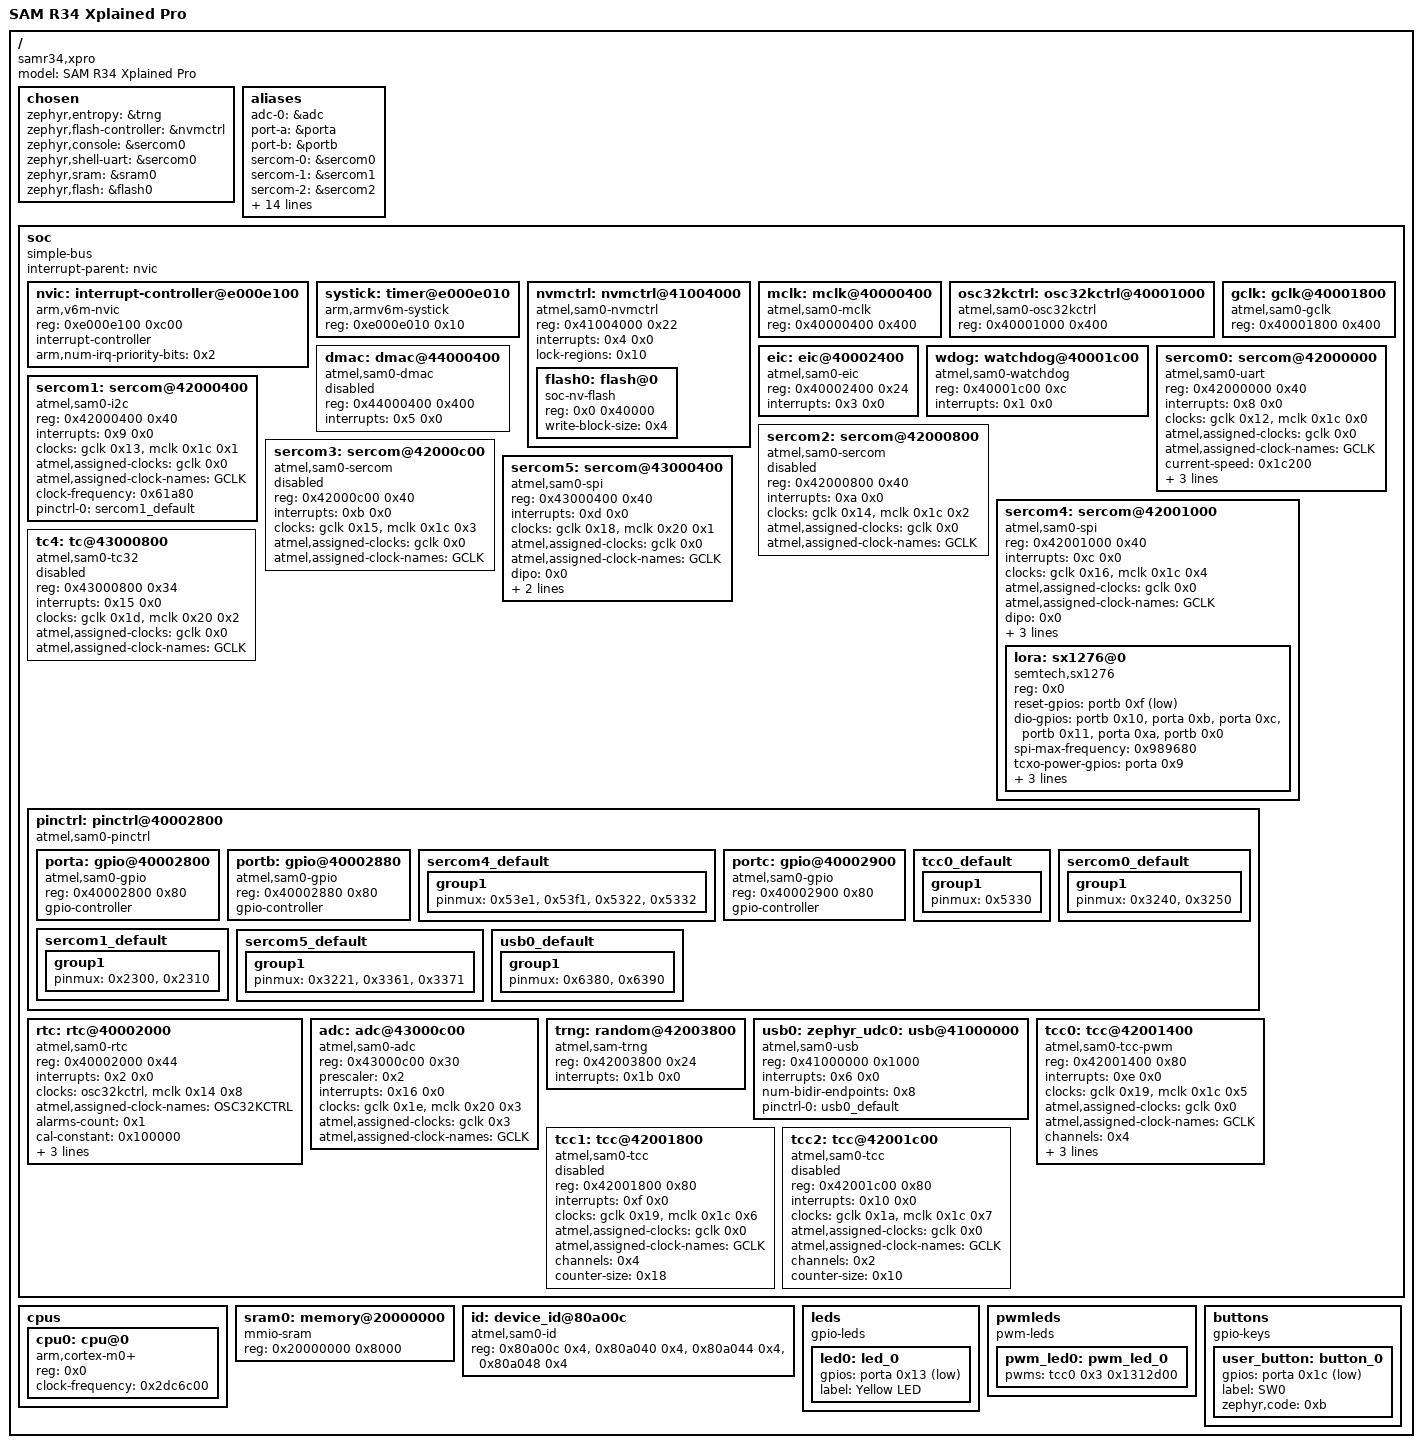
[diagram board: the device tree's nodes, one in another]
/dts-v1/;

/* node '/' defined in zephyr/dts/common/skeleton.dtsi:9 */
/ {
	#address-cells = < 0x1 >;        /* in zephyr/dts/common/skeleton.dtsi:10 */
	#size-cells = < 0x1 >;           /* in zephyr/dts/common/skeleton.dtsi:11 */
	model = "SAM R34 Xplained Pro";  /* in zephyr/boards/atmel/sam0/samr34_xpro/samr34_xpro.dts:14 */
	compatible = "samr34,xpro",
	             "atmel,samr34j18b",
	             "atmel,samr34";     /* in zephyr/boards/atmel/sam0/samr34_xpro/samr34_xpro.dts:15 */

	/* node '/chosen' defined in zephyr/dts/common/skeleton.dtsi:13 */
	chosen {
		zephyr,entropy = &trng;             /* in zephyr/dts/arm/atmel/saml2x.dtsi:37 */
		zephyr,flash-controller = &nvmctrl; /* in zephyr/dts/arm/atmel/saml2x.dtsi:38 */
		zephyr,console = &sercom0;          /* in zephyr/boards/atmel/sam0/samr34_xpro/samr34_xpro.dts:18 */
		zephyr,shell-uart = &sercom0;       /* in zephyr/boards/atmel/sam0/samr34_xpro/samr34_xpro.dts:19 */
		zephyr,sram = &sram0;               /* in zephyr/boards/atmel/sam0/samr34_xpro/samr34_xpro.dts:20 */
		zephyr,flash = &flash0;             /* in zephyr/boards/atmel/sam0/samr34_xpro/samr34_xpro.dts:21 */
	};

	/* node '/aliases' defined in zephyr/dts/common/skeleton.dtsi:15 */
	aliases {
		adc-0 = &adc;         /* in zephyr/dts/arm/atmel/saml2x.dtsi:17 */
		port-a = &porta;      /* in zephyr/dts/arm/atmel/saml2x.dtsi:19 */
		port-b = &portb;      /* in zephyr/dts/arm/atmel/saml2x.dtsi:20 */
		sercom-0 = &sercom0;  /* in zephyr/dts/arm/atmel/saml2x.dtsi:22 */
		sercom-1 = &sercom1;  /* in zephyr/dts/arm/atmel/saml2x.dtsi:23 */
		sercom-2 = &sercom2;  /* in zephyr/dts/arm/atmel/saml2x.dtsi:24 */
		sercom-3 = &sercom3;  /* in zephyr/dts/arm/atmel/saml2x.dtsi:25 */
		sercom-4 = &sercom4;  /* in zephyr/dts/arm/atmel/saml2x.dtsi:26 */
		sercom-5 = &sercom5;  /* in zephyr/dts/arm/atmel/saml2x.dtsi:27 */
		rtc = &rtc;           /* in zephyr/dts/arm/atmel/saml2x.dtsi:29 */
		tc-4 = &tc4;          /* in zephyr/dts/arm/atmel/saml2x.dtsi:31 */
		watchdog0 = &wdog;    /* in zephyr/dts/arm/atmel/saml2x.dtsi:33 */
		tcc-0 = &tcc0;        /* in zephyr/dts/arm/atmel/saml21.dtsi:12 */
		tcc-1 = &tcc1;        /* in zephyr/dts/arm/atmel/saml21.dtsi:13 */
		tcc-2 = &tcc2;        /* in zephyr/dts/arm/atmel/saml21.dtsi:14 */
		port-c = &portc;      /* in zephyr/dts/arm/atmel/samr34.dtsi:16 */
		lora0 = &lora;        /* in zephyr/dts/arm/atmel/samr34.dtsi:18 */
		led0 = &led0;         /* in zephyr/boards/atmel/sam0/samr34_xpro/samr34_xpro.dts:26 */
		pwm-led0 = &pwm_led0; /* in zephyr/boards/atmel/sam0/samr34_xpro/samr34_xpro.dts:27 */
		sw0 = &user_button;   /* in zephyr/boards/atmel/sam0/samr34_xpro/samr34_xpro.dts:28 */
	};

	/* node '/soc' defined in zephyr/dts/arm/armv6-m.dtsi:6 */
	soc {
		#address-cells = < 0x1 >;     /* in zephyr/dts/arm/armv6-m.dtsi:7 */
		#size-cells = < 0x1 >;        /* in zephyr/dts/arm/armv6-m.dtsi:8 */
		compatible = "simple-bus";    /* in zephyr/dts/arm/armv6-m.dtsi:9 */
		interrupt-parent = < &nvic >; /* in zephyr/dts/arm/armv6-m.dtsi:10 */
		ranges;                       /* in zephyr/dts/arm/armv6-m.dtsi:11 */

		/* node '/soc/interrupt-controller@e000e100' defined in zephyr/dts/arm/armv6-m.dtsi:13 */
		nvic: interrupt-controller@e000e100 {
			#address-cells = < 0x1 >;            /* in zephyr/dts/arm/armv6-m.dtsi:14 */
			compatible = "arm,v6m-nvic";         /* in zephyr/dts/arm/armv6-m.dtsi:15 */
			reg = < 0xe000e100 0xc00 >;          /* in zephyr/dts/arm/armv6-m.dtsi:16 */
			interrupt-controller;                /* in zephyr/dts/arm/armv6-m.dtsi:17 */
			#interrupt-cells = < 0x2 >;          /* in zephyr/dts/arm/armv6-m.dtsi:18 */
			arm,num-irq-priority-bits = < 0x2 >; /* in zephyr/dts/arm/atmel/saml2x.dtsi:249 */
			phandle = < 0x1 >;                   /* in zephyr/dts/arm/armv6-m.dtsi:10 */
		};

		/* node '/soc/timer@e000e010' defined in zephyr/dts/arm/armv6-m.dtsi:21 */
		systick: timer@e000e010 {
			compatible = "arm,armv6m-systick"; /* in zephyr/dts/arm/armv6-m.dtsi:22 */
			reg = < 0xe000e010 0x10 >;         /* in zephyr/dts/arm/armv6-m.dtsi:23 */
		};

		/* node '/soc/nvmctrl@41004000' defined in zephyr/dts/arm/atmel/saml2x.dtsi:67 */
		nvmctrl: nvmctrl@41004000 {
			compatible = "atmel,sam0-nvmctrl"; /* in zephyr/dts/arm/atmel/saml2x.dtsi:68 */
			reg = < 0x41004000 0x22 >;         /* in zephyr/dts/arm/atmel/saml2x.dtsi:69 */
			interrupts = < 0x4 0x0 >;          /* in zephyr/dts/arm/atmel/saml2x.dtsi:70 */
			#address-cells = < 0x1 >;          /* in zephyr/dts/arm/atmel/saml2x.dtsi:72 */
			#size-cells = < 0x1 >;             /* in zephyr/dts/arm/atmel/saml2x.dtsi:73 */
			lock-regions = < 0x10 >;           /* in zephyr/dts/arm/atmel/saml2x.dtsi:75 */

			/* node '/soc/nvmctrl@41004000/flash@0' defined in zephyr/dts/arm/atmel/saml2x.dtsi:77 */
			flash0: flash@0 {
				compatible = "soc-nv-flash"; /* in zephyr/dts/arm/atmel/saml2x.dtsi:78 */
				reg = < 0x0 0x40000 >;       /* in zephyr/dts/arm/atmel/saml2x.dtsi:79 */
				write-block-size = < 0x4 >;  /* in zephyr/dts/arm/atmel/saml2x.dtsi:81 */
			};
		};

		/* node '/soc/mclk@40000400' defined in zephyr/dts/arm/atmel/saml2x.dtsi:85 */
		mclk: mclk@40000400 {
			compatible = "atmel,sam0-mclk"; /* in zephyr/dts/arm/atmel/saml2x.dtsi:86 */
			reg = < 0x40000400 0x400 >;     /* in zephyr/dts/arm/atmel/saml2x.dtsi:87 */
			#clock-cells = < 0x2 >;         /* in zephyr/dts/arm/atmel/saml2x.dtsi:89 */
			phandle = < 0x3 >;              /* in zephyr/dts/arm/atmel/saml21.dtsi:72 */
		};

		/* node '/soc/osc32kctrl@40001000' defined in zephyr/dts/arm/atmel/saml2x.dtsi:92 */
		osc32kctrl: osc32kctrl@40001000 {
			compatible = "atmel,sam0-osc32kctrl";  /* in zephyr/dts/arm/atmel/saml2x.dtsi:93 */
			reg = < 0x40001000 0x400 >;            /* in zephyr/dts/arm/atmel/saml2x.dtsi:94 */
			#clock-cells = < 0x0 >;                /* in zephyr/dts/arm/atmel/saml2x.dtsi:96 */
			#atmel,assigned-clock-cells = < 0x1 >; /* in zephyr/dts/arm/atmel/saml2x.dtsi:97 */
			phandle = < 0xa >;                     /* in zephyr/dts/arm/atmel/saml2x.dtsi:203 */
		};

		/* node '/soc/gclk@40001800' defined in zephyr/dts/arm/atmel/saml2x.dtsi:100 */
		gclk: gclk@40001800 {
			compatible = "atmel,sam0-gclk";        /* in zephyr/dts/arm/atmel/saml2x.dtsi:101 */
			reg = < 0x40001800 0x400 >;            /* in zephyr/dts/arm/atmel/saml2x.dtsi:102 */
			#clock-cells = < 0x1 >;                /* in zephyr/dts/arm/atmel/saml2x.dtsi:104 */
			#atmel,assigned-clock-cells = < 0x1 >; /* in zephyr/dts/arm/atmel/saml2x.dtsi:105 */
			phandle = < 0x2 >;                     /* in zephyr/dts/arm/atmel/saml21.dtsi:72 */
		};

		/* node '/soc/dmac@44000400' defined in zephyr/dts/arm/atmel/saml2x.dtsi:108 */
		dmac: dmac@44000400 {
			compatible = "atmel,sam0-dmac"; /* in zephyr/dts/arm/atmel/saml2x.dtsi:109 */
			reg = < 0x44000400 0x400 >;     /* in zephyr/dts/arm/atmel/saml2x.dtsi:110 */
			interrupts = < 0x5 0x0 >;       /* in zephyr/dts/arm/atmel/saml2x.dtsi:111 */
			status = "disabled";            /* in zephyr/dts/arm/atmel/saml2x.dtsi:112 */
			#dma-cells = < 0x2 >;           /* in zephyr/dts/arm/atmel/saml2x.dtsi:114 */
		};

		/* node '/soc/eic@40002400' defined in zephyr/dts/arm/atmel/saml2x.dtsi:117 */
		eic: eic@40002400 {
			compatible = "atmel,sam0-eic"; /* in zephyr/dts/arm/atmel/saml2x.dtsi:118 */
			reg = < 0x40002400 0x24 >;     /* in zephyr/dts/arm/atmel/saml2x.dtsi:119 */
			interrupts = < 0x3 0x0 >;      /* in zephyr/dts/arm/atmel/saml2x.dtsi:120 */
		};

		/* node '/soc/watchdog@40001c00' defined in zephyr/dts/arm/atmel/saml2x.dtsi:123 */
		wdog: watchdog@40001c00 {
			compatible = "atmel,sam0-watchdog"; /* in zephyr/dts/arm/atmel/saml2x.dtsi:124 */
			reg = < 0x40001c00 0xc >;           /* in zephyr/dts/arm/atmel/saml2x.dtsi:125 */
			interrupts = < 0x1 0x0 >;           /* in zephyr/dts/arm/atmel/saml2x.dtsi:126 */
		};

		/* node '/soc/sercom@42000000' defined in zephyr/dts/arm/atmel/saml2x.dtsi:129 */
		sercom0: sercom@42000000 {
			reg = < 0x42000000 0x40 >;             /* in zephyr/dts/arm/atmel/saml2x.dtsi:131 */
			interrupts = < 0x8 0x0 >;              /* in zephyr/dts/arm/atmel/saml21.dtsi:71 */
			clocks = < &gclk 0x12 >,
			         < &mclk 0x1c 0x0 >;           /* in zephyr/dts/arm/atmel/saml21.dtsi:72 */
			clock-names = "GCLK",
			              "MCLK";                  /* in zephyr/dts/arm/atmel/saml21.dtsi:73 */
			atmel,assigned-clocks = < &gclk 0x0 >; /* in zephyr/dts/arm/atmel/saml21.dtsi:74 */
			atmel,assigned-clock-names = "GCLK";   /* in zephyr/dts/arm/atmel/saml21.dtsi:75 */
			status = "okay";                       /* in zephyr/boards/atmel/sam0/samr34_xpro/samr34_xpro.dts:87 */
			compatible = "atmel,sam0-uart";        /* in zephyr/boards/atmel/sam0/samr34_xpro/samr34_xpro.dts:88 */
			current-speed = < 0x1c200 >;           /* in zephyr/boards/atmel/sam0/samr34_xpro/samr34_xpro.dts:89 */
			rxpo = < 0x1 >;                        /* in zephyr/boards/atmel/sam0/samr34_xpro/samr34_xpro.dts:90 */
			txpo = < 0x0 >;                        /* in zephyr/boards/atmel/sam0/samr34_xpro/samr34_xpro.dts:91 */
			pinctrl-0 = < &sercom0_default >;      /* in zephyr/boards/atmel/sam0/samr34_xpro/samr34_xpro.dts:93 */
			pinctrl-names = "default";             /* in zephyr/boards/atmel/sam0/samr34_xpro/samr34_xpro.dts:94 */
		};

		/* node '/soc/sercom@42000400' defined in zephyr/dts/arm/atmel/saml2x.dtsi:135 */
		sercom1: sercom@42000400 {
			reg = < 0x42000400 0x40 >;             /* in zephyr/dts/arm/atmel/saml2x.dtsi:137 */
			interrupts = < 0x9 0x0 >;              /* in zephyr/dts/arm/atmel/saml21.dtsi:79 */
			clocks = < &gclk 0x13 >,
			         < &mclk 0x1c 0x1 >;           /* in zephyr/dts/arm/atmel/saml21.dtsi:80 */
			clock-names = "GCLK",
			              "MCLK";                  /* in zephyr/dts/arm/atmel/saml21.dtsi:81 */
			atmel,assigned-clocks = < &gclk 0x0 >; /* in zephyr/dts/arm/atmel/saml21.dtsi:82 */
			atmel,assigned-clock-names = "GCLK";   /* in zephyr/dts/arm/atmel/saml21.dtsi:83 */
			status = "okay";                       /* in zephyr/boards/atmel/sam0/samr34_xpro/samr34_xpro.dts:98 */
			compatible = "atmel,sam0-i2c";         /* in zephyr/boards/atmel/sam0/samr34_xpro/samr34_xpro.dts:99 */
			clock-frequency = < 0x61a80 >;         /* in zephyr/boards/atmel/sam0/samr34_xpro/samr34_xpro.dts:100 */
			#address-cells = < 0x1 >;              /* in zephyr/boards/atmel/sam0/samr34_xpro/samr34_xpro.dts:101 */
			#size-cells = < 0x0 >;                 /* in zephyr/boards/atmel/sam0/samr34_xpro/samr34_xpro.dts:102 */
			pinctrl-0 = < &sercom1_default >;      /* in zephyr/boards/atmel/sam0/samr34_xpro/samr34_xpro.dts:104 */
			pinctrl-names = "default";             /* in zephyr/boards/atmel/sam0/samr34_xpro/samr34_xpro.dts:105 */
		};

		/* node '/soc/sercom@42000800' defined in zephyr/dts/arm/atmel/saml2x.dtsi:141 */
		sercom2: sercom@42000800 {
			compatible = "atmel,sam0-sercom";      /* in zephyr/dts/arm/atmel/saml2x.dtsi:142 */
			reg = < 0x42000800 0x40 >;             /* in zephyr/dts/arm/atmel/saml2x.dtsi:143 */
			status = "disabled";                   /* in zephyr/dts/arm/atmel/saml2x.dtsi:144 */
			interrupts = < 0xa 0x0 >;              /* in zephyr/dts/arm/atmel/saml21.dtsi:87 */
			clocks = < &gclk 0x14 >,
			         < &mclk 0x1c 0x2 >;           /* in zephyr/dts/arm/atmel/saml21.dtsi:88 */
			clock-names = "GCLK",
			              "MCLK";                  /* in zephyr/dts/arm/atmel/saml21.dtsi:89 */
			atmel,assigned-clocks = < &gclk 0x0 >; /* in zephyr/dts/arm/atmel/saml21.dtsi:90 */
			atmel,assigned-clock-names = "GCLK";   /* in zephyr/dts/arm/atmel/saml21.dtsi:91 */
		};

		/* node '/soc/sercom@42000c00' defined in zephyr/dts/arm/atmel/saml2x.dtsi:147 */
		sercom3: sercom@42000c00 {
			compatible = "atmel,sam0-sercom";      /* in zephyr/dts/arm/atmel/saml2x.dtsi:148 */
			reg = < 0x42000c00 0x40 >;             /* in zephyr/dts/arm/atmel/saml2x.dtsi:149 */
			status = "disabled";                   /* in zephyr/dts/arm/atmel/saml2x.dtsi:150 */
			interrupts = < 0xb 0x0 >;              /* in zephyr/dts/arm/atmel/saml21.dtsi:95 */
			clocks = < &gclk 0x15 >,
			         < &mclk 0x1c 0x3 >;           /* in zephyr/dts/arm/atmel/saml21.dtsi:96 */
			clock-names = "GCLK",
			              "MCLK";                  /* in zephyr/dts/arm/atmel/saml21.dtsi:97 */
			atmel,assigned-clocks = < &gclk 0x0 >; /* in zephyr/dts/arm/atmel/saml21.dtsi:98 */
			atmel,assigned-clock-names = "GCLK";   /* in zephyr/dts/arm/atmel/saml21.dtsi:99 */
		};

		/* node '/soc/sercom@42001000' defined in zephyr/dts/arm/atmel/saml2x.dtsi:153 */
		sercom4: sercom@42001000 {
			reg = < 0x42001000 0x40 >;             /* in zephyr/dts/arm/atmel/saml2x.dtsi:155 */
			interrupts = < 0xc 0x0 >;              /* in zephyr/dts/arm/atmel/saml21.dtsi:103 */
			clocks = < &gclk 0x16 >,
			         < &mclk 0x1c 0x4 >;           /* in zephyr/dts/arm/atmel/saml21.dtsi:104 */
			clock-names = "GCLK",
			              "MCLK";                  /* in zephyr/dts/arm/atmel/saml21.dtsi:105 */
			atmel,assigned-clocks = < &gclk 0x0 >; /* in zephyr/dts/arm/atmel/saml21.dtsi:106 */
			atmel,assigned-clock-names = "GCLK";   /* in zephyr/dts/arm/atmel/saml21.dtsi:107 */
			compatible = "atmel,sam0-spi";         /* in zephyr/dts/arm/atmel/samr34.dtsi:42 */
			#address-cells = < 0x1 >;              /* in zephyr/dts/arm/atmel/samr34.dtsi:45 */
			#size-cells = < 0x0 >;                 /* in zephyr/dts/arm/atmel/samr34.dtsi:46 */
			dipo = < 0x0 >;                        /* in zephyr/dts/arm/atmel/samr34.dtsi:48 */
			dopo = < 0x1 >;                        /* in zephyr/dts/arm/atmel/samr34.dtsi:49 */
			cs-gpios = < &portb 0x1f 0x1 >;        /* in zephyr/dts/arm/atmel/samr34.dtsi:50 */
			pinctrl-0 = < &sercom4_default >;      /* in zephyr/dts/arm/atmel/samr34.dtsi:52 */
			pinctrl-names = "default";             /* in zephyr/dts/arm/atmel/samr34.dtsi:53 */
			status = "okay";                       /* in zephyr/boards/atmel/sam0/samr34_xpro/samr34_xpro.dts:110 */

			/* node '/soc/sercom@42001000/sx1276@0' defined in zephyr/dts/arm/atmel/samr34.dtsi:55 */
			lora: sx1276@0 {
				compatible = "semtech,sx1276";         /* in zephyr/dts/arm/atmel/samr34.dtsi:56 */
				reg = < 0x0 >;                         /* in zephyr/dts/arm/atmel/samr34.dtsi:57 */
				reset-gpios = < &portb 0xf 0x1 >;      /* in zephyr/dts/arm/atmel/samr34.dtsi:60 */
				dio-gpios = < &portb 0x10 0x20 >,
				            < &porta 0xb 0x20 >,
				            < &porta 0xc 0x20 >,
				            < &portb 0x11 0x20 >,
				            < &porta 0xa 0x20 >,
				            < &portb 0x0 0x20 >;       /* in zephyr/dts/arm/atmel/samr34.dtsi:61 */
				spi-max-frequency = < 0x989680 >;      /* in zephyr/dts/arm/atmel/samr34.dtsi:67 */
				status = "okay";                       /* in zephyr/boards/atmel/sam0/samr34_xpro/samr34_xpro.dts:114 */
				tcxo-power-gpios = < &porta 0x9 0x0 >; /* in zephyr/boards/atmel/sam0/samr34_xpro/samr34_xpro.dts:116 */
				tcxo-power-startup-delay-ms = < 0x5 >; /* in zephyr/boards/atmel/sam0/samr34_xpro/samr34_xpro.dts:117 */
				rfi-enable-gpios = < &porta 0xd 0x0 >; /* in zephyr/boards/atmel/sam0/samr34_xpro/samr34_xpro.dts:118 */
				rfo-enable-gpios = < &porta 0xd 0x0 >; /* in zephyr/boards/atmel/sam0/samr34_xpro/samr34_xpro.dts:119 */
			};
		};

		/* node '/soc/sercom@43000400' defined in zephyr/dts/arm/atmel/saml2x.dtsi:159 */
		sercom5: sercom@43000400 {
			reg = < 0x43000400 0x40 >;             /* in zephyr/dts/arm/atmel/saml2x.dtsi:161 */
			interrupts = < 0xd 0x0 >;              /* in zephyr/dts/arm/atmel/saml21.dtsi:111 */
			clocks = < &gclk 0x18 >,
			         < &mclk 0x20 0x1 >;           /* in zephyr/dts/arm/atmel/saml21.dtsi:112 */
			clock-names = "GCLK",
			              "MCLK";                  /* in zephyr/dts/arm/atmel/saml21.dtsi:113 */
			atmel,assigned-clocks = < &gclk 0x0 >; /* in zephyr/dts/arm/atmel/saml21.dtsi:114 */
			atmel,assigned-clock-names = "GCLK";   /* in zephyr/dts/arm/atmel/saml21.dtsi:115 */
			status = "okay";                       /* in zephyr/boards/atmel/sam0/samr34_xpro/samr34_xpro.dts:123 */
			compatible = "atmel,sam0-spi";         /* in zephyr/boards/atmel/sam0/samr34_xpro/samr34_xpro.dts:124 */
			dipo = < 0x0 >;                        /* in zephyr/boards/atmel/sam0/samr34_xpro/samr34_xpro.dts:125 */
			dopo = < 0x1 >;                        /* in zephyr/boards/atmel/sam0/samr34_xpro/samr34_xpro.dts:126 */
			#address-cells = < 0x1 >;              /* in zephyr/boards/atmel/sam0/samr34_xpro/samr34_xpro.dts:127 */
			#size-cells = < 0x0 >;                 /* in zephyr/boards/atmel/sam0/samr34_xpro/samr34_xpro.dts:128 */
			pinctrl-0 = < &sercom5_default >;      /* in zephyr/boards/atmel/sam0/samr34_xpro/samr34_xpro.dts:130 */
			pinctrl-names = "default";             /* in zephyr/boards/atmel/sam0/samr34_xpro/samr34_xpro.dts:131 */
		};

		/* node '/soc/tc@43000800' defined in zephyr/dts/arm/atmel/saml2x.dtsi:165 */
		tc4: tc@43000800 {
			compatible = "atmel,sam0-tc32";        /* in zephyr/dts/arm/atmel/saml2x.dtsi:166 */
			reg = < 0x43000800 0x34 >;             /* in zephyr/dts/arm/atmel/saml2x.dtsi:167 */
			status = "disabled";                   /* in zephyr/dts/arm/atmel/saml2x.dtsi:168 */
			interrupts = < 0x15 0x0 >;             /* in zephyr/dts/arm/atmel/saml21.dtsi:119 */
			clocks = < &gclk 0x1d >,
			         < &mclk 0x20 0x2 >;           /* in zephyr/dts/arm/atmel/saml21.dtsi:120 */
			clock-names = "GCLK",
			              "MCLK";                  /* in zephyr/dts/arm/atmel/saml21.dtsi:121 */
			atmel,assigned-clocks = < &gclk 0x0 >; /* in zephyr/dts/arm/atmel/saml21.dtsi:122 */
			atmel,assigned-clock-names = "GCLK";   /* in zephyr/dts/arm/atmel/saml21.dtsi:123 */
		};

		/* node '/soc/pinctrl@40002800' defined in zephyr/dts/arm/atmel/saml2x.dtsi:171 */
		pinctrl: pinctrl@40002800 {
			compatible = "atmel,sam0-pinctrl";        /* in zephyr/dts/arm/atmel/saml2x.dtsi:172 */
			#address-cells = < 0x1 >;                 /* in zephyr/dts/arm/atmel/saml2x.dtsi:175 */
			#size-cells = < 0x1 >;                    /* in zephyr/dts/arm/atmel/saml2x.dtsi:176 */
			ranges = < 0x40002800 0x40002800 0x180 >; /* in zephyr/dts/arm/atmel/samr34.dtsi:23 */

			/* node '/soc/pinctrl@40002800/gpio@40002800' defined in zephyr/dts/arm/atmel/saml2x.dtsi:178 */
			porta: gpio@40002800 {
				compatible = "atmel,sam0-gpio"; /* in zephyr/dts/arm/atmel/saml2x.dtsi:179 */
				reg = < 0x40002800 0x80 >;      /* in zephyr/dts/arm/atmel/saml2x.dtsi:180 */
				#atmel,pin-cells = < 0x2 >;     /* in zephyr/dts/arm/atmel/saml2x.dtsi:182 */
				#gpio-cells = < 0x2 >;          /* in zephyr/dts/arm/atmel/saml2x.dtsi:183 */
				gpio-controller;                /* in zephyr/dts/arm/atmel/saml2x.dtsi:185 */
				phandle = < 0x8 >;              /* in zephyr/dts/arm/atmel/samr34.dtsi:61 */
			};

			/* node '/soc/pinctrl@40002800/gpio@40002880' defined in zephyr/dts/arm/atmel/saml2x.dtsi:188 */
			portb: gpio@40002880 {
				compatible = "atmel,sam0-gpio"; /* in zephyr/dts/arm/atmel/saml2x.dtsi:189 */
				reg = < 0x40002880 0x80 >;      /* in zephyr/dts/arm/atmel/saml2x.dtsi:190 */
				#atmel,pin-cells = < 0x2 >;     /* in zephyr/dts/arm/atmel/saml2x.dtsi:192 */
				#gpio-cells = < 0x2 >;          /* in zephyr/dts/arm/atmel/saml2x.dtsi:193 */
				gpio-controller;                /* in zephyr/dts/arm/atmel/saml2x.dtsi:195 */
				phandle = < 0x6 >;              /* in zephyr/dts/arm/atmel/samr34.dtsi:50 */
			};

			/* node '/soc/pinctrl@40002800/sercom4_default' defined in zephyr/dts/arm/atmel/samr34-pinctrl.dtsi:10 */
			sercom4_default: sercom4_default {
				phandle = < 0x7 >; /* in zephyr/dts/arm/atmel/samr34.dtsi:52 */

				/* node '/soc/pinctrl@40002800/sercom4_default/group1' defined in zephyr/dts/arm/atmel/samr34-pinctrl.dtsi:11 */
				group1 {
					pinmux = < 0x53e1 >,
					         < 0x53f1 >,
					         < 0x5322 >,
					         < 0x5332 >; /* in zephyr/dts/arm/atmel/samr34-pinctrl.dtsi:12 */
				};
			};

			/* node '/soc/pinctrl@40002800/gpio@40002900' defined in zephyr/dts/arm/atmel/samr34.dtsi:25 */
			portc: gpio@40002900 {
				compatible = "atmel,sam0-gpio"; /* in zephyr/dts/arm/atmel/samr34.dtsi:26 */
				reg = < 0x40002900 0x80 >;      /* in zephyr/dts/arm/atmel/samr34.dtsi:27 */
				#atmel,pin-cells = < 0x2 >;     /* in zephyr/dts/arm/atmel/samr34.dtsi:29 */
				#gpio-cells = < 0x2 >;          /* in zephyr/dts/arm/atmel/samr34.dtsi:30 */
				gpio-controller;                /* in zephyr/dts/arm/atmel/samr34.dtsi:32 */
			};

			/* node '/soc/pinctrl@40002800/tcc0_default' defined in zephyr/boards/atmel/sam0/samr34_xpro/samr34_xpro-pinctrl.dtsi:10 */
			tcc0_default: tcc0_default {
				phandle = < 0xc >; /* in zephyr/boards/atmel/sam0/samr34_xpro/samr34_xpro.dts:74 */

				/* node '/soc/pinctrl@40002800/tcc0_default/group1' defined in zephyr/boards/atmel/sam0/samr34_xpro/samr34_xpro-pinctrl.dtsi:11 */
				group1 {
					pinmux = < 0x5330 >; /* in zephyr/boards/atmel/sam0/samr34_xpro/samr34_xpro-pinctrl.dtsi:12 */
				};
			};

			/* node '/soc/pinctrl@40002800/sercom0_default' defined in zephyr/boards/atmel/sam0/samr34_xpro/samr34_xpro-pinctrl.dtsi:16 */
			sercom0_default: sercom0_default {
				phandle = < 0x4 >; /* in zephyr/boards/atmel/sam0/samr34_xpro/samr34_xpro.dts:93 */

				/* node '/soc/pinctrl@40002800/sercom0_default/group1' defined in zephyr/boards/atmel/sam0/samr34_xpro/samr34_xpro-pinctrl.dtsi:17 */
				group1 {
					pinmux = < 0x3240 >,
					         < 0x3250 >; /* in zephyr/boards/atmel/sam0/samr34_xpro/samr34_xpro-pinctrl.dtsi:18 */
				};
			};

			/* node '/soc/pinctrl@40002800/sercom1_default' defined in zephyr/boards/atmel/sam0/samr34_xpro/samr34_xpro-pinctrl.dtsi:23 */
			sercom1_default: sercom1_default {
				phandle = < 0x5 >; /* in zephyr/boards/atmel/sam0/samr34_xpro/samr34_xpro.dts:104 */

				/* node '/soc/pinctrl@40002800/sercom1_default/group1' defined in zephyr/boards/atmel/sam0/samr34_xpro/samr34_xpro-pinctrl.dtsi:24 */
				group1 {
					pinmux = < 0x2300 >,
					         < 0x2310 >; /* in zephyr/boards/atmel/sam0/samr34_xpro/samr34_xpro-pinctrl.dtsi:25 */
				};
			};

			/* node '/soc/pinctrl@40002800/sercom5_default' defined in zephyr/boards/atmel/sam0/samr34_xpro/samr34_xpro-pinctrl.dtsi:30 */
			sercom5_default: sercom5_default {
				phandle = < 0x9 >; /* in zephyr/boards/atmel/sam0/samr34_xpro/samr34_xpro.dts:130 */

				/* node '/soc/pinctrl@40002800/sercom5_default/group1' defined in zephyr/boards/atmel/sam0/samr34_xpro/samr34_xpro-pinctrl.dtsi:31 */
				group1 {
					pinmux = < 0x3221 >,
					         < 0x3361 >,
					         < 0x3371 >; /* in zephyr/boards/atmel/sam0/samr34_xpro/samr34_xpro-pinctrl.dtsi:32 */
				};
			};

			/* node '/soc/pinctrl@40002800/usb0_default' defined in zephyr/boards/atmel/sam0/samr34_xpro/samr34_xpro-pinctrl.dtsi:38 */
			usb0_default: usb0_default {
				phandle = < 0xb >; /* in zephyr/boards/atmel/sam0/samr34_xpro/samr34_xpro.dts:137 */

				/* node '/soc/pinctrl@40002800/usb0_default/group1' defined in zephyr/boards/atmel/sam0/samr34_xpro/samr34_xpro-pinctrl.dtsi:39 */
				group1 {
					pinmux = < 0x6380 >,
					         < 0x6390 >; /* in zephyr/boards/atmel/sam0/samr34_xpro/samr34_xpro-pinctrl.dtsi:40 */
				};
			};
		};

		/* node '/soc/rtc@40002000' defined in zephyr/dts/arm/atmel/saml2x.dtsi:199 */
		rtc: rtc@40002000 {
			compatible = "atmel,sam0-rtc";               /* in zephyr/dts/arm/atmel/saml2x.dtsi:200 */
			reg = < 0x40002000 0x44 >;                   /* in zephyr/dts/arm/atmel/saml2x.dtsi:201 */
			interrupts = < 0x2 0x0 >;                    /* in zephyr/dts/arm/atmel/saml2x.dtsi:202 */
			clocks = < &osc32kctrl >,
			         < &mclk 0x14 0x8 >;                 /* in zephyr/dts/arm/atmel/saml2x.dtsi:203 */
			clock-names = "OSC32KCTRL",
			              "MCLK";                        /* in zephyr/dts/arm/atmel/saml2x.dtsi:204 */
			atmel,assigned-clock-names = "OSC32KCTRL";   /* in zephyr/dts/arm/atmel/saml2x.dtsi:206 */
			alarms-count = < 0x1 >;                      /* in zephyr/dts/arm/atmel/saml2x.dtsi:209 */
			cal-constant = < 0x100000 >;                 /* in zephyr/dts/arm/atmel/saml2x.dtsi:210 */
			status = "okay";                             /* in zephyr/boards/atmel/sam0/samr34_xpro/samr34_xpro.dts:79 */
			counter-mode = "clock";                      /* in zephyr/boards/atmel/sam0/samr34_xpro/samr34_xpro.dts:80 */
			prescaler = < 0x400 >;                       /* in zephyr/boards/atmel/sam0/samr34_xpro/samr34_xpro.dts:81 */
			atmel,assigned-clocks = < &osc32kctrl 0x4 >; /* in zephyr/boards/atmel/sam0/samr34_xpro/samr34_xpro.dts:83 */
		};

		/* node '/soc/adc@43000c00' defined in zephyr/dts/arm/atmel/saml2x.dtsi:213 */
		adc: adc@43000c00 {
			compatible = "atmel,sam0-adc";         /* in zephyr/dts/arm/atmel/saml2x.dtsi:214 */
			reg = < 0x43000c00 0x30 >;             /* in zephyr/dts/arm/atmel/saml2x.dtsi:215 */
			#io-channel-cells = < 0x1 >;           /* in zephyr/dts/arm/atmel/saml2x.dtsi:218 */
			prescaler = < 0x2 >;                   /* in zephyr/dts/arm/atmel/saml2x.dtsi:220 */
			interrupts = < 0x16 0x0 >;             /* in zephyr/dts/arm/atmel/saml21.dtsi:127 */
			interrupt-names = "resrdy";            /* in zephyr/dts/arm/atmel/saml21.dtsi:128 */
			clocks = < &gclk 0x1e >,
			         < &mclk 0x20 0x3 >;           /* in zephyr/dts/arm/atmel/saml21.dtsi:129 */
			clock-names = "GCLK",
			              "MCLK";                  /* in zephyr/dts/arm/atmel/saml21.dtsi:130 */
			atmel,assigned-clocks = < &gclk 0x3 >; /* in zephyr/dts/arm/atmel/saml21.dtsi:136 */
			atmel,assigned-clock-names = "GCLK";   /* in zephyr/dts/arm/atmel/saml21.dtsi:137 */
			status = "okay";                       /* in zephyr/boards/atmel/sam0/samr34_xpro/samr34_xpro.dts:64 */
		};

		/* node '/soc/random@42003800' defined in zephyr/dts/arm/atmel/saml2x.dtsi:231 */
		trng: random@42003800 {
			compatible = "atmel,sam-trng"; /* in zephyr/dts/arm/atmel/saml2x.dtsi:232 */
			reg = < 0x42003800 0x24 >;     /* in zephyr/dts/arm/atmel/saml2x.dtsi:233 */
			interrupts = < 0x1b 0x0 >;     /* in zephyr/dts/arm/atmel/saml2x.dtsi:234 */
		};

		/* node '/soc/usb@41000000' defined in zephyr/dts/arm/atmel/saml2x.dtsi:237 */
		usb0: zephyr_udc0: usb@41000000 {
			compatible = "atmel,sam0-usb"; /* in zephyr/dts/arm/atmel/saml2x.dtsi:238 */
			reg = < 0x41000000 0x1000 >;   /* in zephyr/dts/arm/atmel/saml2x.dtsi:239 */
			interrupts = < 0x6 0x0 >;      /* in zephyr/dts/arm/atmel/saml2x.dtsi:240 */
			num-bidir-endpoints = < 0x8 >; /* in zephyr/dts/arm/atmel/saml2x.dtsi:243 */
			status = "okay";               /* in zephyr/boards/atmel/sam0/samr34_xpro/samr34_xpro.dts:135 */
			pinctrl-0 = < &usb0_default >; /* in zephyr/boards/atmel/sam0/samr34_xpro/samr34_xpro.dts:137 */
			pinctrl-names = "default";     /* in zephyr/boards/atmel/sam0/samr34_xpro/samr34_xpro.dts:138 */
		};

		/* node '/soc/tcc@42001400' defined in zephyr/dts/arm/atmel/saml21.dtsi:18 */
		tcc0: tcc@42001400 {
			reg = < 0x42001400 0x80 >;             /* in zephyr/dts/arm/atmel/saml21.dtsi:20 */
			interrupts = < 0xe 0x0 >;              /* in zephyr/dts/arm/atmel/saml21.dtsi:21 */
			clocks = < &gclk 0x19 >,
			         < &mclk 0x1c 0x5 >;           /* in zephyr/dts/arm/atmel/saml21.dtsi:22 */
			clock-names = "GCLK",
			              "MCLK";                  /* in zephyr/dts/arm/atmel/saml21.dtsi:23 */
			atmel,assigned-clocks = < &gclk 0x0 >; /* in zephyr/dts/arm/atmel/saml21.dtsi:24 */
			atmel,assigned-clock-names = "GCLK";   /* in zephyr/dts/arm/atmel/saml21.dtsi:25 */
			channels = < 0x4 >;                    /* in zephyr/dts/arm/atmel/saml21.dtsi:28 */
			counter-size = < 0x18 >;               /* in zephyr/dts/arm/atmel/saml21.dtsi:29 */
			status = "okay";                       /* in zephyr/boards/atmel/sam0/samr34_xpro/samr34_xpro.dts:68 */
			compatible = "atmel,sam0-tcc-pwm";     /* in zephyr/boards/atmel/sam0/samr34_xpro/samr34_xpro.dts:69 */
			prescaler = < 0x4 >;                   /* in zephyr/boards/atmel/sam0/samr34_xpro/samr34_xpro.dts:71 */
			#pwm-cells = < 0x2 >;                  /* in zephyr/boards/atmel/sam0/samr34_xpro/samr34_xpro.dts:72 */
			pinctrl-0 = < &tcc0_default >;         /* in zephyr/boards/atmel/sam0/samr34_xpro/samr34_xpro.dts:74 */
			pinctrl-names = "default";             /* in zephyr/boards/atmel/sam0/samr34_xpro/samr34_xpro.dts:75 */
			phandle = < 0xd >;                     /* in zephyr/boards/atmel/sam0/samr34_xpro/samr34_xpro.dts:44 */
		};

		/* node '/soc/tcc@42001800' defined in zephyr/dts/arm/atmel/saml21.dtsi:32 */
		tcc1: tcc@42001800 {
			compatible = "atmel,sam0-tcc";         /* in zephyr/dts/arm/atmel/saml21.dtsi:33 */
			reg = < 0x42001800 0x80 >;             /* in zephyr/dts/arm/atmel/saml21.dtsi:34 */
			interrupts = < 0xf 0x0 >;              /* in zephyr/dts/arm/atmel/saml21.dtsi:35 */
			clocks = < &gclk 0x19 >,
			         < &mclk 0x1c 0x6 >;           /* in zephyr/dts/arm/atmel/saml21.dtsi:36 */
			clock-names = "GCLK",
			              "MCLK";                  /* in zephyr/dts/arm/atmel/saml21.dtsi:37 */
			atmel,assigned-clocks = < &gclk 0x0 >; /* in zephyr/dts/arm/atmel/saml21.dtsi:38 */
			atmel,assigned-clock-names = "GCLK";   /* in zephyr/dts/arm/atmel/saml21.dtsi:39 */
			status = "disabled";                   /* in zephyr/dts/arm/atmel/saml21.dtsi:40 */
			channels = < 0x4 >;                    /* in zephyr/dts/arm/atmel/saml21.dtsi:42 */
			counter-size = < 0x18 >;               /* in zephyr/dts/arm/atmel/saml21.dtsi:43 */
		};

		/* node '/soc/tcc@42001c00' defined in zephyr/dts/arm/atmel/saml21.dtsi:46 */
		tcc2: tcc@42001c00 {
			compatible = "atmel,sam0-tcc";         /* in zephyr/dts/arm/atmel/saml21.dtsi:47 */
			reg = < 0x42001c00 0x80 >;             /* in zephyr/dts/arm/atmel/saml21.dtsi:48 */
			interrupts = < 0x10 0x0 >;             /* in zephyr/dts/arm/atmel/saml21.dtsi:49 */
			clocks = < &gclk 0x1a >,
			         < &mclk 0x1c 0x7 >;           /* in zephyr/dts/arm/atmel/saml21.dtsi:50 */
			clock-names = "GCLK",
			              "MCLK";                  /* in zephyr/dts/arm/atmel/saml21.dtsi:51 */
			atmel,assigned-clocks = < &gclk 0x0 >; /* in zephyr/dts/arm/atmel/saml21.dtsi:52 */
			atmel,assigned-clock-names = "GCLK";   /* in zephyr/dts/arm/atmel/saml21.dtsi:53 */
			status = "disabled";                   /* in zephyr/dts/arm/atmel/saml21.dtsi:54 */
			channels = < 0x2 >;                    /* in zephyr/dts/arm/atmel/saml21.dtsi:56 */
			counter-size = < 0x10 >;               /* in zephyr/dts/arm/atmel/saml21.dtsi:57 */
		};
	};

	/* node '/cpus' defined in zephyr/dts/arm/atmel/saml2x.dtsi:41 */
	cpus {
		#address-cells = < 0x1 >; /* in zephyr/dts/arm/atmel/saml2x.dtsi:42 */
		#size-cells = < 0x0 >;    /* in zephyr/dts/arm/atmel/saml2x.dtsi:43 */

		/* node '/cpus/cpu@0' defined in zephyr/dts/arm/atmel/saml2x.dtsi:45 */
		cpu0: cpu@0 {
			compatible = "arm,cortex-m0+";   /* in zephyr/dts/arm/atmel/saml2x.dtsi:46 */
			reg = < 0x0 >;                   /* in zephyr/dts/arm/atmel/saml2x.dtsi:47 */
			device_type = "cpu";             /* in zephyr/dts/arm/atmel/saml2x.dtsi:49 */
			clock-frequency = < 0x2dc6c00 >; /* in zephyr/boards/atmel/sam0/samr34_xpro/samr34_xpro.dts:60 */
		};
	};

	/* node '/memory@20000000' defined in zephyr/dts/arm/atmel/saml2x.dtsi:53 */
	sram0: memory@20000000 {
		compatible = "mmio-sram";    /* in zephyr/dts/arm/atmel/saml2x.dtsi:54 */
		reg = < 0x20000000 0x8000 >; /* in zephyr/dts/arm/atmel/saml2x.dtsi:55 */
	};

	/* node '/device_id@80a00c' defined in zephyr/dts/arm/atmel/saml2x.dtsi:58 */
	id: device_id@80a00c {
		compatible = "atmel,sam0-id"; /* in zephyr/dts/arm/atmel/saml2x.dtsi:59 */
		reg = < 0x80a00c 0x4 >,
		      < 0x80a040 0x4 >,
		      < 0x80a044 0x4 >,
		      < 0x80a048 0x4 >;       /* in zephyr/dts/arm/atmel/saml2x.dtsi:60 */
	};

	/* node '/leds' defined in zephyr/boards/atmel/sam0/samr34_xpro/samr34_xpro.dts:31 */
	leds {
		compatible = "gpio-leds"; /* in zephyr/boards/atmel/sam0/samr34_xpro/samr34_xpro.dts:32 */

		/* node '/leds/led_0' defined in zephyr/boards/atmel/sam0/samr34_xpro/samr34_xpro.dts:34 */
		led0: led_0 {
			gpios = < &porta 0x13 0x1 >; /* in zephyr/boards/atmel/sam0/samr34_xpro/samr34_xpro.dts:35 */
			label = "Yellow LED";        /* in zephyr/boards/atmel/sam0/samr34_xpro/samr34_xpro.dts:36 */
		};
	};

	/* node '/pwmleds' defined in zephyr/boards/atmel/sam0/samr34_xpro/samr34_xpro.dts:40 */
	pwmleds {
		compatible = "pwm-leds"; /* in zephyr/boards/atmel/sam0/samr34_xpro/samr34_xpro.dts:41 */

		/* node '/pwmleds/pwm_led_0' defined in zephyr/boards/atmel/sam0/samr34_xpro/samr34_xpro.dts:43 */
		pwm_led0: pwm_led_0 {
			pwms = < &tcc0 0x3 0x1312d00 >; /* in zephyr/boards/atmel/sam0/samr34_xpro/samr34_xpro.dts:44 */
		};
	};

	/* node '/buttons' defined in zephyr/boards/atmel/sam0/samr34_xpro/samr34_xpro.dts:48 */
	buttons {
		compatible = "gpio-keys"; /* in zephyr/boards/atmel/sam0/samr34_xpro/samr34_xpro.dts:49 */

		/* node '/buttons/button_0' defined in zephyr/boards/atmel/sam0/samr34_xpro/samr34_xpro.dts:51 */
		user_button: button_0 {
			gpios = < &porta 0x1c 0x11 >; /* in zephyr/boards/atmel/sam0/samr34_xpro/samr34_xpro.dts:52 */
			label = "SW0";                /* in zephyr/boards/atmel/sam0/samr34_xpro/samr34_xpro.dts:53 */
			zephyr,code = < 0xb >;        /* in zephyr/boards/atmel/sam0/samr34_xpro/samr34_xpro.dts:54 */
		};
	};
};
